# STM32H7B0xxQ register map
File version: 1.0
Registers are 32-bit, read-write, reset 0x0 unless marked. A register's access mark holds for its fields unless they carry their own. Offsets are from the block's base; [hi:lo] are bit positions; {n}, {i} and the like mark numbered series.

## OPAMP — Operational Amplifier (OPAMP)
Base 0x40009000
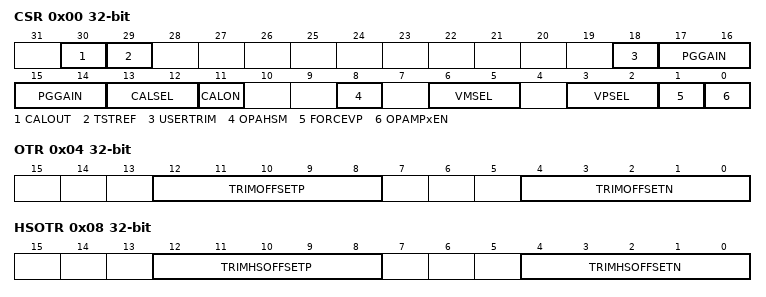
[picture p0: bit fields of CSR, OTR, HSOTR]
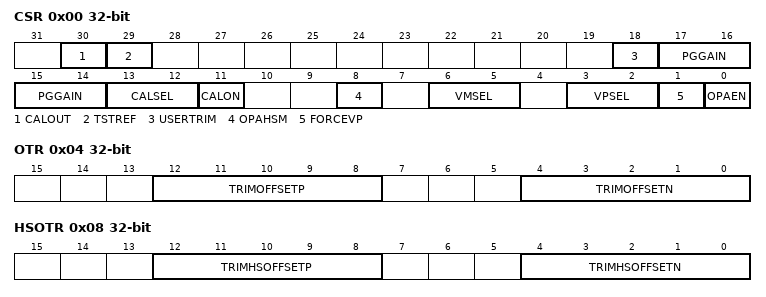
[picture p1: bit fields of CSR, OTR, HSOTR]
0x00 CSR — OPAMP control/status register
  [30] CALOUT — Operational amplifier calibration output
  [29] TSTREF — OpAmp calibration reference voltage output control
  [18] USERTRIM — User trimming enable
    0=FACTORY (OPAMP trimming factors set to factory values); 1=USER (OPAMP trimming factors set to user values)
  [17:14] PGGAIN — Operational amplifier Programmable amplifier gain value
  [13:12] CALSEL — Calibration selection
  [11] CALON — Calibration mode enable
    0=FUNCTIONAL (OPAMP functional mode); 1=CALIBRATION (OPAMP calibration mode)
  [8] OPAHSM — Operational amplifier high speed mode
  [6:5] VMSEL — Inverting input selection
    0=IO0; 1=IO1; 2=CONNECT_NO
  [3:2] VPSEL — Non inverted input selection
    0=IO0; 1=DAC; 2=DAC2
  [1] FORCEVP — Force internal reference on VP
  [0] OPAMPxEN — OPAMP enable
0x04 OTR — OPAMP
  [12:8] TRIMOFFSETP — Trim for PMOS differential pairs
  [4:0] TRIMOFFSETN — Trim for NMOS differential pairs
0x08 HSOTR — OPAMP
  [12:8] TRIMHSOFFSETP — Trim for PMOS differential pairs
  [4:0] TRIMHSOFFSETN — Trim for NMOS differential pairs

## OPAMP1 — Operational Amplifier (OPAMP)
Base 0x40009000; alternate view of OPAMP
Same registers: OPAMP2 0x40009010
0x00 CSR — OPAMP control/status register
  [30] CALOUT — Operational amplifier1 calibration output
  [29] TSTREF — OpAmp calibration reference voltage output control
  [18] USERTRIM — User trimming enable
  [17:14] PGGAIN — Operational amplifier1 Programmable amplifier gain value
  [13:12] CALSEL — Calibration selection
  [11] CALON — Calibration mode enable
  [8] OPAHSM — Operational amplifier1 high speed mode
  [6:5] VMSEL — Inverting input selection
  [3:2] VPSEL — Non inverted input selection
  [1] FORCEVP — Force internal reference on VP
  [0] OPAEN — Operational amplifier1 Enable
0x04 OTR — OPAMP
  [12:8] TRIMOFFSETP — Trim for PMOS differential pairs
  [4:0] TRIMOFFSETN — Trim for NMOS differential pairs
0x08 HSOTR — OPAMP
  [12:8] TRIMHSOFFSETP — Trim for PMOS differential pairs
  [4:0] TRIMHSOFFSETN — Trim for NMOS differential pairs

## MDIOS
Base 0x40009400
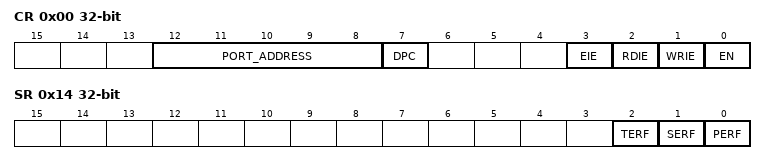
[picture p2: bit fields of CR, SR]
0x00 CR
  [12:8] PORT_ADDRESS — MDIOS slave port address mask
  [7] DPC — MDIOS slave disable preamble check
  [3] EIE — MDIOS slave register error interrupt enable
  [2] RDIE — MDIOS slave register read interrupt enable
  [1] WRIE — MDIOS slave register write interrupt enable
  [0] EN — MDIOS slave peripheral enable
0x04 WRFR
0x08 CWRFR
0x0C RDFR
0x10 CRDFR
0x14 SR
  [2] TERF — MDIOS slave preamble error flag
  [1] SERF — MDIOS slave start error flag
  [0] PERF — MDIOS slave turnaround error flag
0x18 CLRFR
{0x100+4i} DINR{i} (i=0..31)
{0x180+4i} DOUTR{i} (i=0..31)

## FDCAN_CCU — FD Controller Area Network
Base 0x4000A800
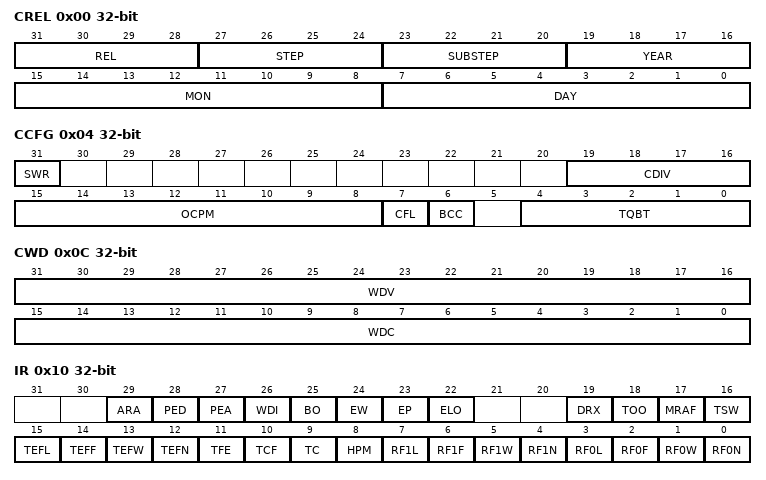
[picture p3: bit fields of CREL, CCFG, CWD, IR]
0x00 CREL — Clock Calibration Unit Core Release register
  [31:28] REL — Core release
  [27:24] STEP — Step of Core release
  [23:20] SUBSTEP — Sub-step of Core release
  [19:16] YEAR — Timestamp Year
  [15:8] MON — Timestamp Month
  [7:0] DAY — Timestamp Day
0x04 CCFG — Calibration Configuration register
  [31] SWR — Software Reset
  [19:16] CDIV — Clock Divider
  [15:8] OCPM — Oscillator Clock Periods Minimum
  [7] CFL — Calibration Field Length
  [6] BCC — Bypass Clock Calibration
  [4:0] TQBT — Time Quanta per Bit Time
0x08 CSTAT — Calibration Status register
0x0C CWD — Calibration Watchdog register
  [31:16] WDV — Watchdog Value
  [15:0] WDC — Watchdog Configuration
0x10 IR — CCU Interrupt register
  [29] ARA — Access to Reserved Address
  [28] PED — Protocol Error in Data Phase
  [27] PEA — Protocol Error in Arbitration Phase
  [26] WDI — Watchdog Interrupt
  [25] BO — Bus_Off Status
  [24] EW — Warning Status
  [23] EP — Error Passive
  [22] ELO — Error Logging Overflow
  [19] DRX — Message stored to Dedicated Rx Buffer
  [18] TOO — Timeout Occurred
  [17] MRAF — Message RAM Access Failure
  [16] TSW — Timestamp Wraparound
  [15] TEFL — Tx Event FIFO Element Lost
  [14] TEFF — Tx Event FIFO Full
  [13] TEFW — Tx Event FIFO Watermark Reached
  [12] TEFN — Tx Event FIFO New Entry
  [11] TFE — Tx FIFO Empty
  [10] TCF — Transmission Cancellation Finished
  [9] TC — Transmission Completed
  [8] HPM — High Priority Message
  [7] RF1L — Rx FIFO 1 Message Lost
  [6] RF1F — Rx FIFO 1 Full
  [5] RF1W — Rx FIFO 1 Watermark Reached
  [4] RF1N — Rx FIFO 1 New Message
  [3] RF0L — Rx FIFO 0 Message Lost
  [2] RF0F — Rx FIFO 0 Full
  [1] RF0W — Rx FIFO 0 Watermark Reached
  [0] RF0N — Rx FIFO 0 New Message
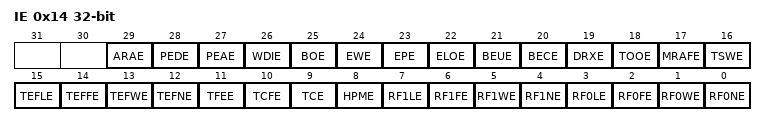
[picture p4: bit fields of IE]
0x14 IE — CCU Interrupt Enable register
  [29] ARAE — Access to Reserved Address Enable
  [28] PEDE — Protocol Error in Data Phase Enable
  [27] PEAE — Protocol Error in Arbitration Phase Enable
  [26] WDIE — Watchdog Interrupt Enable
  [25] BOE — Bus_Off Status Enable
  [24] EWE — Warning Status Enable
  [23] EPE — Error Passive Enable
  [22] ELOE — Error Logging Overflow Enable
  [21] BEUE — Bit Error Uncorrected Interrupt Enable
  [20] BECE — Bit Error Corrected Interrupt Enable
  [19] DRXE — Message stored to Dedicated Rx Buffer Enable
  [18] TOOE — Timeout Occurred Enable
  [17] MRAFE — Message RAM Access Failure Enable
  [16] TSWE — Timestamp Wraparound Enable
  [15] TEFLE — Tx Event FIFO Element Lost Enable
  [14] TEFFE — Tx Event FIFO Full Enable
  [13] TEFWE — Tx Event FIFO Watermark Reached Enable
  [12] TEFNE — Tx Event FIFO New Entry Enable
  [11] TFEE — Tx FIFO Empty Enable
  [10] TCFE — Transmission Cancellation Finished Enable
  [9] TCE — Transmission Completed Enable
  [8] HPME — High Priority Message Enable
  [7] RF1LE — Rx FIFO 1 Message Lost Enable
  [6] RF1FE — Rx FIFO 1 Full Enable
  [5] RF1WE — Rx FIFO 1 Watermark Reached Enable
  [4] RF1NE — Rx FIFO 1 New Message Enable
  [3] RF0LE — Rx FIFO 0 Message Lost Enable
  [2] RF0FE — Rx FIFO 0 Full Enable
  [1] RF0WE — Rx FIFO 0 Watermark Reached Enable
  [0] RF0NE — Rx FIFO 0 New Message Enable
